# nrf52 register map
Vendor: Nordic Semiconductor; Series: nrf52; File version: 1
CPU: CM4 r0p1, little endian, MPU, FPU, 3 interrupt priority bits
Registers are 32-bit, read-write, reset 0x0 unless marked. A register's access mark holds for its fields unless they carry their own. Offsets are from the block's base; [hi:lo] are bit positions; 'fields as' and 'values as' point back to an identical list.

## TWI0 — I2C compatible Two-Wire Interface 0
Base 0x40003000; alternate view of SPI0
Same registers: TWI1 0x40004000 (alternate view of SPI1)
0x00 TASKS_STARTRX wo — Start TWI receive sequence
  [0] TASKS_STARTRX
    1=Trigger task
0x08 TASKS_STARTTX wo — Start TWI transmit sequence
  [0] TASKS_STARTTX
    1=Trigger task
0x14 TASKS_STOP wo — Stop TWI transaction
  [0] TASKS_STOP
    1=Trigger task
0x1C TASKS_SUSPEND wo — Suspend TWI transaction
  [0] TASKS_SUSPEND
    1=Trigger task
0x20 TASKS_RESUME wo — Resume TWI transaction
  [0] TASKS_RESUME
    1=Trigger task
0x104 EVENTS_STOPPED — TWI stopped
  [0] EVENTS_STOPPED
    0=NotGenerated (Event not generated); 1=Generated (Event generated)
0x108 EVENTS_RXDREADY — TWI RXD byte received
  [0] EVENTS_RXDREADY
    values as EVENTS_STOPPED.EVENTS_STOPPED
0x11C EVENTS_TXDSENT — TWI TXD byte sent
  [0] EVENTS_TXDSENT
    values as EVENTS_STOPPED.EVENTS_STOPPED
0x124 EVENTS_ERROR — TWI error
  [0] EVENTS_ERROR
    values as EVENTS_STOPPED.EVENTS_STOPPED
0x138 EVENTS_BB — TWI byte boundary, generated before each byte that is sent or received
  [0] EVENTS_BB
    values as EVENTS_STOPPED.EVENTS_STOPPED
0x148 EVENTS_SUSPENDED — TWI entered the suspended state
  [0] EVENTS_SUSPENDED
    values as EVENTS_STOPPED.EVENTS_STOPPED
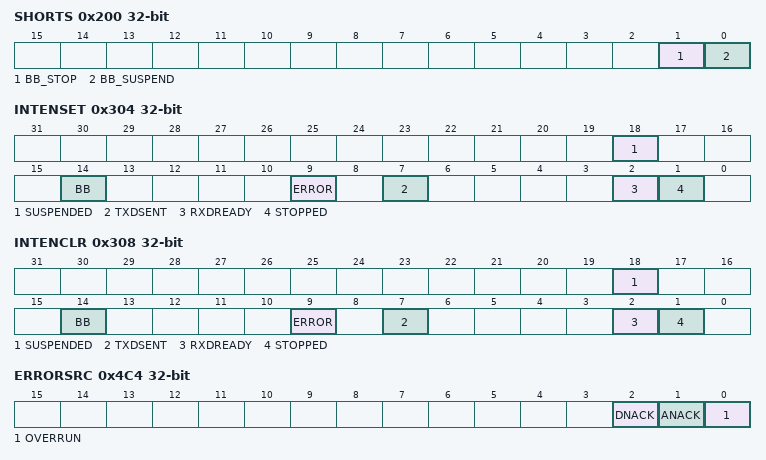
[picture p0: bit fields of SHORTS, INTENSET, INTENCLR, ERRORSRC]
0x200 SHORTS — Shortcuts between local events and tasks
  [1] BB_STOP — Shortcut between event BB and task STOP
    0=Disabled (Disable shortcut); 1=Enabled (Enable shortcut)
  [0] BB_SUSPEND — Shortcut between event BB and task SUSPEND
    0=Disabled (Disable shortcut); 1=Enabled (Enable shortcut)
0x304 INTENSET — Enable interrupt
  [all] fields
    on read: 0=Disabled (Read: Disabled); 1=Enabled (Read: Enabled) | on write: 1=Set (Enable)
  [18] SUSPENDED — Write '1' to enable interrupt for event SUSPENDED
  [14] BB — Write '1' to enable interrupt for event BB
  [9] ERROR — Write '1' to enable interrupt for event ERROR
  [7] TXDSENT — Write '1' to enable interrupt for event TXDSENT
  [2] RXDREADY — Write '1' to enable interrupt for event RXDREADY
  [1] STOPPED — Write '1' to enable interrupt for event STOPPED
0x308 INTENCLR — Disable interrupt
  [all] fields
    on read: 0=Disabled (Read: Disabled); 1=Enabled (Read: Enabled) | on write: 1=Clear (Disable)
  [18] SUSPENDED — Write '1' to disable interrupt for event SUSPENDED
  [14] BB — Write '1' to disable interrupt for event BB
  [9] ERROR — Write '1' to disable interrupt for event ERROR
  [7] TXDSENT — Write '1' to disable interrupt for event TXDSENT
  [2] RXDREADY — Write '1' to disable interrupt for event RXDREADY
  [1] STOPPED — Write '1' to disable interrupt for event STOPPED
0x4C4 ERRORSRC write-1-clears — Error source
  [2] DNACK — NACK received after sending a data byte (write '1' to clear)
    on read: 0=NotPresent (Read: error not present); 1=Present (Read: error present) | on write: 1=Clear (Write: clear error on writing '1')
  [1] ANACK — NACK received after sending the address (write '1' to clear)
    values as DNACK
  [0] OVERRUN — Overrun error
    on read: 0=NotPresent (Read: no overrun occured); 1=Present (Read: overrun occured) | on write: 1=Clear (Write: clear error on writing '1')
0x500 ENABLE — Enable TWI
  [3:0] ENABLE — Enable or disable TWI
    0=Disabled (Disable TWI); 5=Enabled (Enable TWI)
0x508 PSELSCL reset 0xFFFFFFFF — Pin select for SCL
  [31:0] PSELSCL — Pin number configuration for TWI SCL signal
    0xFFFFFFFF=Disconnected
0x50C PSELSDA reset 0xFFFFFFFF — Pin select for SDA
  [31:0] PSELSDA — Pin number configuration for TWI SDA signal
    0xFFFFFFFF=Disconnected
0x518 RXD ro
  [7:0] RXD
0x51C TXD
  [7:0] TXD
0x524 FREQUENCY reset 0x4000000 — TWI frequency
  [31:0] FREQUENCY — TWI master clock frequency
    0x1980000=K100 (100 kbps); 0x4000000=K250 (250 kbps); 0x6680000=K400 (400 kbps (actual rate 410.256 kbps))
0x588 ADDRESS — Address used in the TWI transfer
  [6:0] ADDRESS

## Notices in the file
Copyright (c) 2010 - 2024, Nordic Semiconductor ASA
All rights reserved.
Redistribution and use in source and binary forms, with or without modification,
are permitted provided that the following conditions are met:
1. Redistributions of source code must retain the above copyright notice, this
list of conditions and the following disclaimer.
2. Redistributions in binary form, except as embedded into a Nordic
Semiconductor ASA integrated circuit in a product or a software update for
such product, must reproduce the above copyright notice, this list of
conditions and the following disclaimer in the documentation and/or other
materials provided with the distribution.
3. Neither the name of Nordic Semiconductor ASA nor the names of its
contributors may be used to endorse or promote products derived from this
software without specific prior written permission.
4. This software, with or without modification, must only be used with a
Nordic Semiconductor ASA integrated circuit.
5. Any software provided in binary form under this license must not be reverse
engineered, decompiled, modified and/or disassembled.
THIS SOFTWARE IS PROVIDED BY NORDIC SEMICONDUCTOR ASA "AS IS" AND ANY EXPRESS
OR IMPLIED WARRANTIES, INCLUDING, BUT NOT LIMITED TO, THE IMPLIED WARRANTIES
OF MERCHANTABILITY, NONINFRINGEMENT, AND FITNESS FOR A PARTICULAR PURPOSE ARE
DISCLAIMED. IN NO EVENT SHALL NORDIC SEMICONDUCTOR ASA OR CONTRIBUTORS BE
LIABLE FOR ANY DIRECT, INDIRECT, INCIDENTAL, SPECIAL, EXEMPLARY, OR
CONSEQUENTIAL DAMAGES (INCLUDING, BUT NOT LIMITED TO, PROCUREMENT OF SUBSTITUTE
GOODS OR SERVICES; LOSS OF USE, DATA, OR PROFITS; OR BUSINESS INTERRUPTION)
HOWEVER CAUSED AND ON ANY THEORY OF LIABILITY, WHETHER IN CONTRACT, STRICT
LIABILITY, OR TORT (INCLUDING NEGLIGENCE OR OTHERWISE) ARISING IN ANY WAY OUT
OF THE USE OF THIS SOFTWARE, EVEN IF ADVISED OF THE POSSIBILITY OF SUCH DAMAGE.
